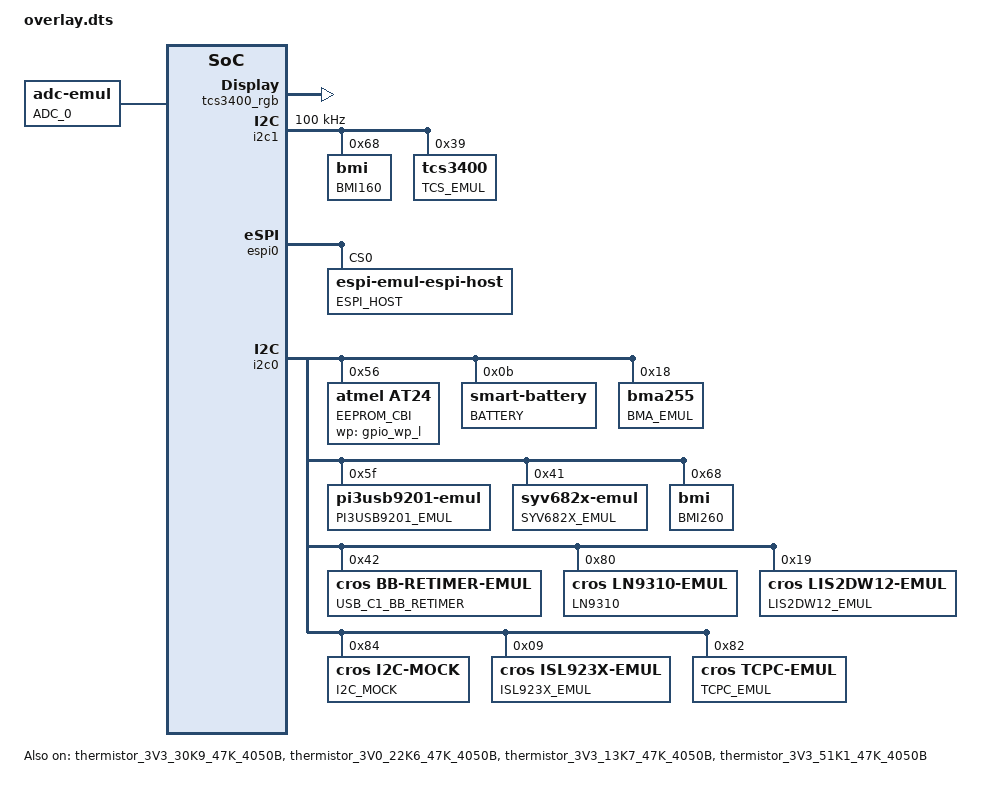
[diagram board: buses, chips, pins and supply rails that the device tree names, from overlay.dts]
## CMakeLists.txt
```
# Copyright 2021 The ChromiumOS Authors
# Use of this source code is governed by a BSD-style license that can be
# found in the LICENSE file.

cmake_minimum_required(VERSION 3.13.1)
find_package(Zephyr REQUIRED HINTS "${ZEPHYR_BASE}")
project(drivers)

add_subdirectory(common)
add_subdirectory(${PLATFORM_EC}/zephyr/test/test_utils test_utils)

get_target_property(TEST_SOURCES app SOURCES)

# Add linked suites here
add_subdirectory_ifdef(CONFIG_LINK_TEST_SUITE_DEFAULT default)
add_subdirectory_ifdef(CONFIG_LINK_TEST_SUITE_DEFAULT_CONSOLE_CMDS default/src/console_cmd)
add_subdirectory_ifdef(CONFIG_LINK_TEST_SUITE_ACPI_STRINGS_FIFO acpi_strings_fifo)
add_subdirectory_ifdef(CONFIG_LINK_TEST_SUITE_AMD_FP6_USB_MUX amd_fp6_usb_mux)
add_subdirectory_ifdef(CONFIG_LINK_TEST_SUITE_ANX7447 anx7447)
add_subdirectory_ifdef(CONFIG_LINK_TEST_SUITE_AP_MUX_CONTROL ap_mux_control)
add_subdirectory_ifdef(CONFIG_LINK_TEST_SUITE_AP_POWER_EVENTS ap_power_events)
add_subdirectory_ifdef(CONFIG_LINK_TEST_SUITE_BMI3XX bmi3xx)
add_subdirectory_ifdef(CONFIG_LINK_TEST_SUITE_BATTERY_CONFIG battery_config)
add_subdirectory_ifdef(CONFIG_LINK_TEST_SUITE_CBI_FLASH cbi_flash)
add_subdirectory_ifdef(CONFIG_LINK_TEST_SUITE_CBI_FLASH_FROM_EEPROM cbi_flash)
add_subdirectory_ifdef(CONFIG_LINK_TEST_SUITE_CEC_COMMON cec_common)
add_subdirectory_ifdef(CONFIG_LINK_TEST_SUITE_CEC_BITBANG cec_bitbang)
add_subdirectory_ifdef(CONFIG_LINK_TEST_SUITE_CEC_IT83XX cec_it83xx)
add_subdirectory_ifdef(CONFIG_LINK_TEST_SUITE_CONSOLE_CMD_CRASH console_cmd_crash)
add_subdirectory_ifdef(CONFIG_LINK_TEST_SUITE_CONSOLE_CMD_MFALLOW console_cmd_mfallow)
add_subdirectory_ifdef(CONFIG_LINK_TEST_SUITE_CONSOLE_BUFFER console_buffer)
add_subdirectory_ifdef(CONFIG_LINK_TEST_SUITE_COMMON_CBI common_cbi)
add_subdirectory_ifdef(CONFIG_LINK_TEST_SUITE_COMMON_CBI_GPIO common_cbi_gpio)
add_subdirectory_ifdef(CONFIG_LINK_TEST_SUITE_COMMON_CHARGER common_charger)
add_subdirectory_ifdef(CONFIG_LINK_TEST_SUITE_CHARGE_MANAGER charge_manager)
add_subdirectory_ifdef(CONFIG_LINK_TEST_SUITE_CHARGESPLASH chargesplash)
add_subdirectory_ifdef(CONFIG_LINK_TEST_SUITE_CROS_FLASH cros_flash)
add_subdirectory_ifdef(CONFIG_LINK_TEST_SUITE_FAN fan)
add_subdirectory_ifdef(CONFIG_LINK_TEST_SUITE_FLASH flash)
add_subdirectory_ifdef(CONFIG_LINK_TEST_SUITE_FPC1025 fpc1025)
add_subdirectory_ifdef(CONFIG_LINK_TEST_SUITE_ICM42607 icm42607)
add_subdirectory_ifdef(CONFIG_LINK_TEST_SUITE_ISL923X isl923x)
add_subdirectory_ifdef(CONFIG_LINK_TEST_SUITE_ISL9241 isl9241)
add_subdirectory_ifdef(CONFIG_LINK_TEST_SUITE_I2C_CONTROLLER i2c_controller)
add_subdirectory_ifdef(CONFIG_LINK_TEST_SUITE_IT8XXX2_HW_SHA256 it8xxx2_hw_sha256)
add_subdirectory_ifdef(CONFIG_LINK_TEST_SUITE_KEYBOARD_8042 keyboard_8042)
add_subdirectory_ifdef(CONFIG_LINK_TEST_SUITE_KEYBOARD_SCAN keyboard_scan)
add_subdirectory_ifdef(CONFIG_LINK_TEST_SUITE_LED_DRIVER led_driver)
add_subdirectory_ifdef(CONFIG_LINK_TEST_SUITE_LED_DRIVER_ALIAS_LED led_driver)
add_subdirectory_ifdef(CONFIG_LINK_TEST_SUITE_LED_DRIVER_CUSTOM led_driver)
add_subdirectory_ifdef(CONFIG_LINK_TEST_SUITE_LED_DRIVER_SEQUENCE led_driver)
add_subdirectory_ifdef(CONFIG_LINK_TEST_SUITE_LED_DRIVER_MAX695X led_driver)
add_subdirectory_ifdef(CONFIG_LINK_TEST_SUITE_LIS2DH lis2dh)
add_subdirectory_ifdef(CONFIG_LINK_TEST_SUITE_LSM6DSM lsm6dsm)
add_subdirectory_ifdef(CONFIG_LINK_TEST_SUITE_MKBP mkbp)
add_subdirectory_ifdef(CONFIG_LINK_TEST_SUITE_NCT38XX nct38xx)
add_subdirectory_ifdef(CONFIG_LINK_TEST_SUITE_NX20P348X nx20p348x)
add_subdirectory_ifdef(CONFIG_LINK_TEST_SUITE_ONE_WIRE_UART one_wire_uart)
add_subdirectory_ifdef(CONFIG_LINK_TEST_SUITE_PANIC panic)
add_subdirectory_ifdef(CONFIG_LINK_TEST_SUITE_PANIC_LOG panic_log)
add_subdirectory_ifdef(CONFIG_LINK_TEST_SUITE_PANIC_OUTPUT panic_output)
add_subdirectory_ifdef(CONFIG_LINK_TEST_SUITE_PRESERVED_RING_BUF preserved_ring_buf)
add_subdirectory_ifdef(CONFIG_LINK_TEST_SUITE_PANIC_REASON panic_reason)
add_subdirectory_ifdef(CONFIG_LINK_TEST_SUITE_POWER_HOST_SLEEP power_host_sleep)
add_subdirectory_ifdef(CONFIG_LINK_TEST_SUITE_RT1718S rt1718s)
add_subdirectory_ifdef(CONFIG_LINK_TEST_SUITE_KTU1125 ktu1125)
add_subdirectory_ifdef(CONFIG_LINK_TEST_SUITE_RAA489000 raa489000)
add_subdirectory_ifdef(CONFIG_LINK_TEST_SUITE_RT1715 rt1715)
add_subdirectory_ifdef(CONFIG_LINK_TEST_SUITE_RT1739 rt1739)
add_subdirectory_ifdef(CONFIG_LINK_TEST_SUITE_RT9490 rt9490)
add_subdirectory_ifdef(CONFIG_LINK_TEST_SUITE_RANDOM random)
add_subdirectory_ifdef(CONFIG_LINK_TEST_SUITE_SHIM_ESPI shim_espi)
add_subdirectory_ifdef(CONFIG_LINK_TEST_SUITE_SHIM_GPIO_ID shim_gpio_id)
add_subdirectory_ifdef(CONFIG_LINK_TEST_SUITE_SHIM_PWM_HC shim_pwm_hc)
add_subdirectory_ifdef(CONFIG_LINK_TEST_SUITE_SHIM_RTC shim_rtc)
add_subdirectory_ifdef(CONFIG_LINK_TEST_SUITE_SMART_BATTERY smart_battery)
add_subdirectory_ifdef(CONFIG_LINK_TEST_SUITE_SMART_BATTERY_PRESENT smart_battery)
add_subdirectory_ifdef(CONFIG_LINK_TEST_SUITE_SMART_BATTERY_DEADBAND smart_battery)
add_subdirectory_ifdef(CONFIG_LINK_TEST_SUITE_TIMER timer)
add_subdirectory_ifdef(CONFIG_LINK_TEST_SUITE_UFSC_PDC ufsc_pdc)
add_subdirectory_ifdef(CONFIG_LINK_TEST_SUITE_UFSC_POLICIES ufsc_policies)
add_subdirectory_ifdef(CONFIG_LINK_TEST_SUITE_UPSTREAM_FUEL_GAUGE upstream_fuel_gauge)
add_subdirectory_ifdef(CONFIG_LINK_TEST_SUITE_USB_COMMON usb_common)
add_subdirectory_ifdef(CONFIG_LINK_TEST_SUITE_USB_MALFUNCTION_SINK usb_malfunction_sink)
add_subdirectory_ifdef(CONFIG_LINK_TEST_SUITE_USB_PD_DISCOVERY usb_pd_discovery)
add_subdirectory_ifdef(CONFIG_LINK_TEST_SUITE_USB_PD_DPS dps)
add_subdirectory_ifdef(CONFIG_LINK_TEST_SUITE_USB_PORT_POWER_DUMB usb_port_power_dumb)
add_subdirectory_ifdef(CONFIG_LINK_TEST_SUITE_USB_RETIMER_FW_UPDATE usb_retimer_fw_update)
add_subdirectory_ifdef(CONFIG_LINK_TEST_SUITE_USBC_ALT_MODE usbc_alt_mode)
add_subdirectory_ifdef(CONFIG_LINK_TEST_SUITE_USBC_CONSOLE_PD usbc_console_pd)
add_subdirectory_ifdef(CONFIG_LINK_TEST_SUITE_USBC_CTVPD usbc_ctvpd)
add_subdirectory_ifdef(CONFIG_LINK_TEST_SUITE_USBC_FRS usbc_frs)
add_subdirectory_ifdef(CONFIG_LINK_TEST_SUITE_USBC_SVDM_DFP_ONLY usbc_svdm_dfp_only)
add_subdirectory_ifdef(CONFIG_LINK_TEST_SUITE_USBC_POWER_CONTRACT usbc_power_contract)
add_subdirectory_ifdef(CONFIG_LINK_TEST_SUITE_USBC_DP_MODE usbc_dp_mode)
add_subdirectory_ifdef(CONFIG_LINK_TEST_SUITE_USBC_TBT_MODE usbc_tbt_mode)
add_subdirectory_ifdef(CONFIG_LINK_TEST_SUITE_USBC_RETIMER usbc_retimer)
add_subdirectory_ifdef(CONFIG_LINK_TEST_SUITE_USBC_USB4_MODE usbc_usb4_mode)
add_subdirectory_ifdef(CONFIG_LINK_TEST_SUITE_USBC_VCONN_SWAP usbc_vconn_swap)
add_subdirectory_ifdef(CONFIG_LINK_TEST_SUITE_USBC_OCP usbc_ocp)
add_subdirectory_ifdef(CONFIG_LINK_TEST_SUITE_USBC_PPC usbc_ppc)
add_subdirectory_ifdef(CONFIG_LINK_TEST_SUITE_USBC_TCPC usbc_tcpc)
add_subdirectory_ifdef(CONFIG_LINK_TEST_SUITE_USBC_SM usbc_sm)
add_subdirectory_ifdef(CONFIG_LINK_TEST_SUITE_USBC_FAKE_PDOS usbc_fake_pdos)
add_subdirectory_ifdef(CONFIG_LINK_TEST_SUITE_HOST_COMMANDS host_cmd)
add_subdirectory_ifdef(CONFIG_LINK_TEST_SUITE_HOST_COMMAND_READ_MEMMAP host_cmd_read_memmap)
add_subdirectory_ifdef(CONFIG_LINK_TEST_SUITE_SYSTEM system)
add_subdirectory_ifdef(CONFIG_LINK_TEST_SUITE_LOCATE_CHIP_ALTS locate_chip)
add_subdirectory_ifdef(CONFIG_LINK_TEST_SUITE_BUTTON button)
add_subdirectory_ifdef(CONFIG_LINK_TEST_SUITE_CONSOLE console)
add_subdirectory_ifdef(CONFIG_LINK_TEST_SUITE_HOST_CMD_THREAD host_command_thread)
add_subdirectory_ifdef(CONFIG_LINK_TEST_SUITE_BC12_UPSTREAM bc12_upstream)
add_subdirectory_ifdef(CONFIG_LINK_TEST_SUITE_PI3USB9201 bc12_pi3usb9201)
add_subdirectory_ifdef(CONFIG_LINK_TEST_SUITE_MEMMAP memmap)
add_subdirectory_ifdef(CONFIG_LINK_TEST_SUITE_LED_COMMON led_common)
add_subdirectory_ifdef(CONFIG_LINK_TEST_SUITE_PS8743 ps8743)
add_subdirectory_ifdef(CONFIG_LINK_TEST_SUITE_PS8XXX ps8xxx)
add_subdirectory_ifdef(CONFIG_LINK_TEST_SUITE_GPIO_INIT gpio_init)
add_subdirectory_ifdef(CONFIG_LINK_TEST_SUITE_GPIO_UNHOOK gpio_unhook)
add_subdirectory_ifdef(CONFIG_LINK_TEST_SUITE_ANX7452 anx7452)
add_subdirectory_ifdef(CONFIG_LINK_TEST_SUITE_KB8010 kb8010)
add_subdirectory_ifdef(CONFIG_LINK_TEST_SUITE_SM5803 sm5803)
add_subdirectory_ifdef(CONFIG_LINK_TEST_SUITE_BODY_DETECTION body_detection)
add_subdirectory_ifdef(CONFIG_LINK_TEST_SUITE_MOTION_SENSE_BUS_AP_OFF motion_sense_bus_ap_off)
add_subdirectory_ifdef(CONFIG_LINK_TEST_SUITE_WATCHDOG watchdog)
add_subdirectory_ifdef(CONFIG_LINK_TEST_SUITE_WATCHDOG_HELPER watchdog_helper)
add_subdirectory_ifdef(CONFIG_LINK_TEST_SUITE_LED_PWM_FADE led_pwm_fade)
add_subdirectory_ifdef(CONFIG_LINK_TEST_SUITE_TABLETMODE_INTERRUPT tabletmode_interrupt)
add_subdirectory_ifdef(CONFIG_LINK_TEST_SUITE_WRITE_PROTECTION_EXTERNAL write_protection_external)
add_subdirectory_ifdef(CONFIG_LINK_TEST_SUITE_IT8XXX2 it8xxx2)
add_subdirectory_ifdef(CONFIG_LINK_TEST_SUITE_RT3645 rt3645)

get_target_property(TEST_SOURCES_NEW app SOURCES)

# Check to make sure at least one suite was added
list(REMOVE_ITEM TEST_SOURCES_NEW ${TEST_SOURCES})
if(NOT TEST_SOURCES_NEW)
  message(FATAL_ERROR "Invalid configuration, must add test sources")
endif()

set_compiler_property(APPEND PROPERTY coverage -O0)
```

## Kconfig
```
# Copyright 2022 The ChromiumOS Authors
# Use of this source code is governed by a BSD-style license that can be
# found in the LICENSE file.

config TEST_PROVIDE_PM_HOOKS
	bool "Provide PM hooks for test purposes"
	default y
	select HAS_PM

config BUG_249829957
	bool "Tracking b/249829957"

config LINK_TEST_SUITE_DEFAULT
	bool "Link and test the default test suite"

config LINK_TEST_SUITE_DEFAULT_CONSOLE_CMDS
	bool "Link and test the default console commands test suite"

config LINK_TEST_SUITE_CONSOLE_BUFFER
	bool "Link and test the console buffer test suite"

config LINK_TEST_SUITE_CONSOLE_CMD_CRASH
	bool "Link and test the console command crash test suite"

config LINK_TEST_SUITE_CONSOLE_CMD_MFALLOW
	bool "Link and test the console command mfallow test suite"

config LINK_TEST_SUITE_ACPI_STRINGS_FIFO
	bool "Link and test the ACPI strings FIFO tests"

config LINK_TEST_SUITE_AMD_FP6_USB_MUX
	bool "Link and test the AMD FP6 USB mux tests"

config LINK_TEST_SUITE_ANX7447
	bool "Link and test the anx7447 tests"

config LINK_TEST_SUITE_AP_MUX_CONTROL
	bool "Link and test the ap_mux_control tests"

config LINK_TEST_SUITE_AP_POWER_EVENTS
	bool "Link and test the ap_power_events driver tests"
	help
	  Verifies the AP power events driver which controls GPIOs
	  based on AP power state transitions.

config LINK_TEST_SUITE_BMI3XX
	bool "Link and test the bmi3xx tests"
	help
	  Include the BMI3XX driver test suite in the
	  binary.

config LINK_TEST_SUITE_BATTERY_CONFIG
	bool "Link and run battery_config CBI tests"
	help
	  Include tests for battery info in CBI.

config LINK_TEST_SUITE_BUTTON
	bool "Link tests for common/button.c"

config LINK_TEST_SUITE_CBI_FLASH
	bool "Link and execute the zephyr/shim/src/cbi/cbi_flash.c tests"
	help
	  Include the CBI Flash storage driver test suite
	  in the binary.

config LINK_TEST_SUITE_CBI_FLASH_FROM_EEPROM
	bool "Link and run CBI EEPROM to flash region tests"
	help
	  Include tests for migrating CBI EEPROM data to the flash based
	  CBI region.

config LINK_TEST_SUITE_CEC_COMMON
	bool "Link and run the common/cec.c tests"

config LINK_TEST_SUITE_CEC_BITBANG
	bool "Link and run tests for driver/cec/bitbang"

config LINK_TEST_SUITE_CEC_IT83XX
	bool "Link and run tests for driver/cec/it83xx"

config LINK_TEST_SUITE_CHARGE_MANAGER
	bool "Link and test the charge manager tests"

config LINK_TEST_SUITE_CHARGESPLASH
	bool "Link and test the chargesplash tests"

config LINK_TEST_SUITE_COMMON_CBI
	bool "Link and execute the common/cbi.c tests"

config LINK_TEST_SUITE_COMMON_CBI_GPIO
	bool "Link and execute the common/cbi_gpio.c tests"

config LINK_TEST_SUITE_COMMON_CHARGER
	bool "Link and execute the common/charger.c tests"

config LINK_TEST_SUITE_FAN
	bool "Link and test the fan tests"

config LINK_TEST_SUITE_CROS_FLASH
	bool "Link and execute the cros-flash driver tests"
	help
	  Include the test suite exercising cros-flash driver in the binary.

config LINK_TEST_SUITE_FLASH
	bool "Link and execute the common/flash.c tests"
	help
	  Include the test suite exercising flash-related code in the binary.

config LINK_TEST_SUITE_GPIO_INIT
  	bool "Link and execute the GPIO init tests"

config LINK_TEST_SUITE_GPIO_UNHOOK
  	bool "Link and execute the unhooked gpio tests"

config LINK_TEST_SUITE_HOST_COMMANDS
	select PLATFORM_EC_CHARGE_STATE_DEBUG
	bool "Link and test the host command tests"

config LINK_TEST_SUITE_HOST_COMMAND_READ_MEMMAP
	bool "Link and test the host command read memmap tests"

config LINK_TEST_SUITE_ICM42607
	bool "Link and test the icm42607 tests"

config LINK_TEST_SUITE_ISL923X
	bool "Link and test the isl923x tests"

config LINK_TEST_SUITE_ISL9241
	bool "Link and test the isl9241 tests"

config LINK_TEST_SUITE_I2C_CONTROLLER
	bool "Link and test the i2c_controller tests"

config LINK_TEST_SUITE_IT8XXX2_HW_SHA256
	bool "Link and test the it8xxx2_hw_sha256 tests"
	help
	  Include the it8xxx2_hw_sha256 test suite
	  in the binary.

config LINK_TEST_SUITE_KEYBOARD_8042
	bool "Link and test the keyboard_8042 tests"

config LINK_TEST_SUITE_KEYBOARD_SCAN
	bool "Link and test the keyboard_scan tests"
	select PLATFORM_EC_MKBP_EVENT_WAKEUP_MASK
	select PLATFORM_EC_MKBP_HOST_EVENT_WAKEUP_MASK

config LINK_TEST_SUITE_LED_DRIVER
	bool "Link and test the led_driver tests"

config LINK_TEST_SUITE_LED_DRIVER_ALIAS_LED
	bool "Link and test the led_driver tests with alias LEDs defined"

config LINK_TEST_SUITE_LED_DRIVER_CUSTOM
	bool "Link and test the LED custom pattern logic"

config LINK_TEST_SUITE_LED_DRIVER_SEQUENCE
	bool "Link and test the LED pattern sequence logic"

config LINK_TEST_SUITE_LOCATE_CHIP_ALTS
	bool "Link tests for alternate operations of the locate chip host cmd"
	help
	  Compile a binary that allows the non herobrine paths of the locate
	  chip command to execute

config LINK_TEST_SUITE_LIS2DH
	bool "Link tests for lis2dh driver"

config LINK_TEST_SUITE_LSM6DSM
	bool "Link tests for lsm6dsm driver"

config LINK_TEST_SUITE_LSM6DSO
	bool "Link tests for lsm6dso driver"

config LINK_TEST_SUITE_LED_DRIVER_MAX695X
	bool "Link and test the MAX695x 7-segment display driver tests"
	help
	  Include the MAX695x driver test suite.
	  Tests the 7-segment LED display driver functionality including
	  initialization, display operations, and console commands.

config LINK_TEST_SUITE_MKBP
	bool "Link and test the mkbp tests"

config LINK_TEST_SUITE_NCT38XX
	bool "Link and test the nct38xx tests"

config LINK_TEST_SUITE_NX20P348X
	bool "Link and test the nx20p348x tests"
	select PLATFORM_EC_CONSOLE_CMD_PPC_DUMP
	select PLATFORM_EC_USB_PD_LOGGING

config LINK_TEST_SUITE_PANIC
	bool "Link and test the panic tests"

config LINK_TEST_SUITE_PANIC_OUTPUT
	bool "Link and test the panic_output tests"

config LINK_TEST_SUITE_PANIC_REASON
	bool "Link and test the panic_reason tests"

config LINK_TEST_SUITE_PANIC_LOG
	bool "Link and test the panic log tests"

config LINK_TEST_SUITE_PRESERVED_RING_BUF
	bool "Link and test the preserved ring buf tests"

config LINK_TEST_SUITE_POWER_HOST_SLEEP
	bool "Link and run the power/host_sleep.c specific tests"

config LINK_TEST_SUITE_PS8743
	bool "Link and test the ps8743 tests"
	help
	  Link tests PS8743 test suite for the MUX driver related function
	  tests.

config LINK_TEST_SUITE_PS8XXX
	bool "Link and test the ps8xxx tests"

config LINK_TEST_SUITE_RAA489000
	bool "Link and test the raa489000 tests"
	help
	  Link raa489000 test suite for the TCPM driver related function
	  tests.

config LINK_TEST_SUITE_RT1715
	bool "Link and test the rt17115 tests"
	help
	  Link rt1715 test suite for the TCPM driver related function
	  tests.

config LINK_TEST_SUITE_IT8XXX2
	bool "Link and test the it8xxx2 tests"
	help
	  Link it8xxx2 test suite for the TCPM driver related function
	  tests.


config LINK_TEST_SUITE_RT1718S
	bool "Link and test the rt1718s tests"
	help
	  Link tests rt1718s test suite for the TCPM driver related function
	  tests.

config LINK_TEST_SUITE_RT1739
	bool "Link and test the rt1739 tests"
	help
	  Link tests rt1739s test suite for the PPC driver related function
	  tests.

config LINK_TEST_SUITE_KTU1125
	bool "Link and test the ktu1125 tests"
	help
	  Link tests ktu1125 test suite for the PPC driver related function
	  tests.

config LINK_TEST_SUITE_RT9490
	bool "Link and test the rt9490 tests"

config LINK_TEST_SUITE_WATCHDOG
	bool "Link and test the watchdog tests"
	select PLATFORM_EC_CONSOLE_CMD_WATCHDOG_INFO
	select PLATFORM_EC_HOSTCMD_WATCHDOG_INFO

config LINK_TEST_SUITE_WATCHDOG_HELPER
	bool "Link and run watchdog helper tests"
	help
	  Include the test suite exercising the Watchdog Helper utility.

config LINK_TEST_SUITE_RANDOM
	bool "Link and run random (trng) tests"
	help
	  Include the test suite exercising RNG code in the binary.

config LINK_TEST_SUITE_SHIM_ESPI
	bool "Link and run the eSPI shim tests"

config LINK_TEST_SUITE_SHIM_GPIO_ID
	bool "Link and run the gpio tests"

config LINK_TEST_SUITE_SHIM_PWM_HC
	bool "Link and run the shim pwm_hc tests"

config LINK_TEST_SUITE_SHIM_RTC
	bool "Link and run the shim rtc tests"

config LINK_TEST_SUITE_SYSTEM
	bool "Link tests for common system code"

config LINK_TEST_SUITE_TIMER
	bool "Link and test the timer tests"

config LINK_TEST_SUITE_UFSC_PDC
	bool "Link and test the UFSC PDC selector"
	help
	  Include the test suite exercising the UFSC PDC selector logic.

config LINK_TEST_SUITE_UFSC_POLICIES
	bool "Link and test the UFSC policies"
	help
	  Include the test suite exercising the UFSC policies.

config LINK_TEST_SUITE_UPSTREAM_FUEL_GAUGE
	bool "Link and test usage of upstream fuel-gauge API"

config LINK_TEST_SUITE_USB_COMMON
	bool "Link and test USB common code tests"

config LINK_TEST_SUITE_USB_PD_DISCOVERY
	bool "Link and test USB PD discovery tests"

config LINK_TEST_SUITE_USB_MALFUNCTION_SINK
	bool "Link and test the usb_malfunction_sink tests"

config LINK_TEST_SUITE_USB_PD_DPS
	bool "Link and test the dps tests"

config LINK_TEST_SUITE_USB_PORT_POWER_DUMB
	bool "Link and test the usb_port_power_dumb tests"

config LINK_TEST_SUITE_USB_RETIMER_FW_UPDATE
	bool "Link and test the usb_retimer_fw_update tests"

config LINK_TEST_SUITE_USBC_ALT_MODE
	bool "Link and test the usbc_alt_mode tests"

config LINK_TEST_SUITE_USBC_CONSOLE_PD
	bool"Link and test the usbc_console_pd tests"

config LINK_TEST_SUITE_USBC_CTVPD
	bool "Link tests for charge-through VCONN-powered device support"
	select EMUL_TCPCI_PARTNER_VPD
	select LOG

config LINK_TEST_SUITE_USBC_FRS
	bool "Link tests for fast role swap support"
	select LOG
	select PLATFORM_EC_USB_PD_FRS

config LINK_TEST_SUITE_USBC_POWER_CONTRACT
	bool "Link tests for USBC Power Contract"
	select LOG

config LINK_TEST_SUITE_USBC_OCP
	bool "Link tests for common USBC OCP code"

config LINK_TEST_SUITE_USBC_PPC
	bool "Link tests for common USBC PPC code"

config LINK_TEST_SUITE_USBC_TCPC
	bool "Link tests for common USBC TCPC code"
	help
	  Include the USBC TCPC test suite in the
	  binary.

config LINK_TEST_SUITE_USBC_SM
	bool "Link tests for common USBC state machine code"
	help
	  Include the USBC SM test suite in the
	  binary.

config LINK_TEST_SUITE_USBC_SVDM_DFP_ONLY
	bool "Link and test the usbc_svdm_dfp_only tests"

config LINK_TEST_SUITE_USBC_RETIMER
	bool "Link the USBC retimer tests"

config LINK_TEST_SUITE_USBC_RETIMER_ANX7483
	bool "Link and test the ANX7484 tests"
	select LINK_TEST_SUITE_USBC_RETIMER
	select PLATFORM_EC_USBC_RETIMER_ANX7483
	help
	  Include the ANX7483 test suite in the binary.

config LINK_TEST_SUITE_USBC_RETIMER_PS8811
	bool "Link and test the PS8811 tests"
	select LINK_TEST_SUITE_USBC_RETIMER
	select PLATFORM_EC_USBC_RETIMER_PS8811
	help
	  Include the PS8811 test suite in the binary.

config LINK_TEST_SUITE_USBC_DP_MODE
	bool "Link and test the usbc_dp_tests"
	help
	  Include the DP 2.1 test suite in the binary, testing the 2.1 SVDM version.

config LINK_TEST_SUITE_USBC_DP_MODE_20
	bool "Link and test the usbc_dp_tests_20"
	help
	  Include the DP 2.1 test suite in the binary, testing the 2.0 SVDM version.

config LINK_TEST_SUITE_USBC_TBT_MODE
	bool "Link and test the usbc_tbt_mode tests"

config LINK_TEST_SUITE_USBC_USB4_MODE
	bool "Link and test the usbc_usb4_mode tests"
	help
	  Include the usbc_usb4 test suite in the binary.

config LINK_TEST_SUITE_USBC_VCONN_SWAP
	bool "Link and test the usbc_vconn_swap tests"
	help
	  Include the test suite exercising VCONN Swap behaviors in the binary.

config LINK_TEST_SUITE_USBC_FAKE_PDOS
	bool "Link and test the usbc_fake_pdos tests"
	help
	  Include the test suite exercising non-standard PDO behaviors in the
	  binary.

config LINK_TEST_SUITE_CONSOLE
	bool "Link and test the console tests"
	select UART_INTERRUPT_DRIVEN

config LINK_TEST_SUITE_HOST_CMD_THREAD
	bool "Link and test the host command thread override tests"

config LINK_TEST_SUITE_BC12_UPSTREAM
	bool "Link and test the BC1.2 upsstream tests"
	help
	  This test suite validates integration of the EC application with
	  the upstream Zephyr BC1.2 driver API.

config LINK_TEST_SUITE_PI3USB9201
	bool "Link and test the pi3usb9201 tests"

config LINK_TEST_SUITE_MEMMAP
	bool "Link and test memory mapped tests for common/flash.c"
	select PLATFORM_EC_MAPPED_STORAGE

config LINK_TEST_SUITE_LED_COMMON
	bool "Link and test the led_common.c file"
	depends on !PLATFORM_EC_LED_DT
	select PLATFORM_EC_LED_COMMON

config LINK_TEST_SUITE_ANX7452
	bool "Link and test the anx7452 tests"
	help
	  Include the test suite of ANX7452 retimer in the binary. The tests
	  use I2C emulation.

config LINK_TEST_SUITE_KB8010
	bool "Link and test the kb8010 tests"
	help
	  Link tests kb8010 test suite for the retimer driver related
	  function tests.

config LINK_TEST_SUITE_SM5803
	bool "Link and test the SM5803 charger tests"

config LINK_TEST_SUITE_BODY_DETECTION
	bool "Link and test the body detection tests"
	help
	  Include the test suite exercising body detection behaviors in the binary.

config LINK_TEST_SUITE_LED_PWM_FADE
	bool "Link and test the led_pwm_fade.c tests"

config LINK_TEST_SUITE_ONE_WIRE_UART
	bool "Link and test the one wire uart driver tests"

config LINK_TEST_SUITE_SMART_BATTERY
	bool "Link and test the smart battery driver tests"

config LINK_TEST_SUITE_SMART_BATTERY_PRESENT
	bool "Link and test the smart battery present driver tests"

config LINK_TEST_SUITE_SMART_BATTERY_DEADBAND
	bool "Link and test the smart battery deadband driver tests"

config LINK_TEST_SUITE_TABLETMODE_INTERRUPT
	bool "Link and test the tabletmode interrupt driver tests"
	help
	  Verifies a singleton driver which handles an external interrupt
	  signaling to the EC when to switch in or out of tablet mode.

config LINK_TEST_SUITE_WRITE_PROTECTION_EXTERNAL
	bool "Link and test the write protection tests"
	help
	  Verifies functionality of external write protection

config LINK_TEST_SUITE_RT3645
	bool "Link and test rt3645 tests"
	help
	  Verifies functionality of rt3645 IMVP driver

source "Kconfig.zephyr"
```

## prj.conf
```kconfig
# Copyright 2021 The ChromiumOS Authors
# Use of this source code is governed by a BSD-style license that can be
# found in the LICENSE file.

# Enabling this config will show all I2C traffic, do not commit with this line
# uncommented, it is here to make it easy to find/enable.
# CONFIG_I2C_LOG_LEVEL_DBG=y

CONFIG_ZTEST=y
CONFIG_ZTEST_ASSERT_VERBOSE=1
CONFIG_ZTEST_MOCKING=y
CONFIG_ZTEST_PARAMETER_COUNT=24
CONFIG_TEST=y
CONFIG_PLATFORM_EC_DEBUG_ASSERT=y
# Do not set CONFIG_ASSERT_TEST=y here, it will mask assert failures.
# Instead set CONFIG_ASSERT_TEST=y only on specific tests that require it.
CONFIG_ASSERT_TEST=n
CONFIG_SHELL_VT100_COMMANDS=n

# Print logs from Zephyr LOG_MODULE to stdout
CONFIG_UART_NATIVE_PTY_0_ON_STDINOUT=y

CONFIG_PLATFORM_EC_AP_HANG_DETECT=y

# Simulate 10 ticks per ms
CONFIG_SYS_CLOCK_TICKS_PER_SEC=10000
CONFIG_TASKS_SET_TEST_RUNNER_TID_RULE=y

# Enable exception stack traces for better errors
CONFIG_EXCEPTION_STACK_TRACE=y

# Enable debugging features
CONFIG_DEBUG=y
CONFIG_X86_DEBUG_INFO=y
CONFIG_DEBUG_OPTIMIZATIONS=y
CONFIG_PLATFORM_EC_CONSOLE_DEBUG=n
CONFIG_SHELL_BACKEND_DUMMY=y
CONFIG_SHELL_BACKEND_SERIAL=n
# Shell dummy backend buffer needs to be big enough to capture reasonably
# large output messages. Note: a buffer larger than 2047 may cause result
# in messages being dropped due to Z_LOG_MSG_MAX_PACKAGE limit.
CONFIG_SHELL_BACKEND_DUMMY_BUF_SIZE=2000
CONFIG_SHELL_HELP=y
# We aren't using the serial console, but there is still a lot of code that
# assumes that a serial port exists.
CONFIG_SERIAL=y
CONFIG_RING_BUFFER=y
CONFIG_PLATFORM_EC_I2C_DEBUG_PASSTHRU=y

# Logging is configured to send output to the shell, disable
# the UART backed to prevent duplicate messages in the output.
CONFIG_LOG_BACKEND_UART=n

CONFIG_PLATFORM_EC=y
CONFIG_CROS_EC=y
CONFIG_SHIMMED_TASKS=y
CONFIG_EMUL=y
CONFIG_GPIO=y
CONFIG_PLATFORM_EC_GPIO_INIT_PRIORITY=49
CONFIG_EEPROM=y
CONFIG_EEPROM_SIMULATOR=n
CONFIG_EEPROM_AT2X_EMUL=y
CONFIG_EMUL_TCPCI_PARTNER_DRP=y
CONFIG_EMUL_TCPCI_PARTNER_FAULTY_EXT=y
CONFIG_PLATFORM_EC_CHARGE_MANAGER=y
CONFIG_PLATFORM_EC_CHARGE_RAMP_SW=y
CONFIG_PLATFORM_EC_CHARGESPLASH=y

CONFIG_PLATFORM_EC_POWERSEQ=y
CONFIG_PLATFORM_EC_CMD_PWR_AVG=y

CONFIG_PLATFORM_EC_EXTPOWER_GPIO=y

CONFIG_PLATFORM_EC_USB_PID=0x5000
CONFIG_PLATFORM_EC_USBC=y
CONFIG_PLATFORM_EC_USB_CHARGER=y
CONFIG_PLATFORM_EC_USB_POWER_DELIVERY=y
CONFIG_PLATFORM_EC_USB_PD_5V_EN_CUSTOM=y
CONFIG_PLATFORM_EC_CHARGER_DISCHARGE_ON_AC=y
CONFIG_PLATFORM_EC_CHARGER_DISCHARGE_ON_AC_CHARGER=y
<<<<<<< PATCH SET (744bca2e0323062202b4f00c09bb1573e3df7eeb charge_control: Support persisting charge limit to BBRAM)
CONFIG_PLATFORM_EC_CHARGE_CONTROL_PERSIST_TO_BBRAM=y
CONFIG_PLATFORM_EC_CHARGE_STATE_DEBUG=y
||||||| BASE      (61760131fbf53ec740a9e456fdf7a2f1b4fe04cf zephyr: system: Add BBRAM support for charge control persist)
CONFIG_PLATFORM_EC_CHARGE_STATE_DEBUG=y
=======
>>>>>>> BASE      (048bed6a24fd4275df284514a3b550a120449414 zephyr: system: Add BBRAM support for charge control persist)
CONFIG_PLATFORM_EC_I2C_VIRTUAL_BATTERY=y
CONFIG_PLATFORM_EC_CHARGER_SENSE_RESISTOR=10
CONFIG_PLATFORM_EC_CHARGER_SENSE_RESISTOR_AC=10
CONFIG_PLATFORM_EC_CHARGER_ISL9238=y
CONFIG_PLATFORM_EC_CHIP_INIT_ROM_REGION=y
CONFIG_PLATFORM_EC_USB_PD_VBUS_MEASURE_CHARGER=y
CONFIG_PLATFORM_EC_USB_PD_FRS=y
CONFIG_PLATFORM_EC_USB_PD_FRS_PPC=y
CONFIG_PLATFORM_EC_USB_PD_REV30=y
CONFIG_PLATFORM_EC_BATTERY_FUEL_GAUGE=y
CONFIG_PLATFORM_EC_HOSTCMD=y
CONFIG_PLATFORM_EC_USB_PD_TCPM_TUSB422=y
CONFIG_PLATFORM_EC_USB_MUX_RUNTIME_CONFIG=y
CONFIG_PLATFORM_EC_TEMP_SENSOR_POWER=y
CONFIG_PLATFORM_EC_SWITCH=y
CONFIG_PLATFORM_EC_SWITCHCAP_LN9310=y
CONFIG_PLATFORM_EC_ACCEL_BMA255=y
CONFIG_PLATFORM_EC_ACCELGYRO_BMI160=y
CONFIG_PLATFORM_EC_ACCELGYRO_BMI260=y
CONFIG_PLATFORM_EC_ACCELGYRO_BMI_COMM_I2C=y
CONFIG_PLATFORM_EC_ACCEL_FIFO=y
CONFIG_PLATFORM_EC_SENSOR_TIGHT_TIMESTAMPS=y
CONFIG_PLATFORM_EC_USB_PD_DISCHARGE=n
CONFIG_PLATFORM_EC_USB_PD_TCPM_MUX=y
CONFIG_PLATFORM_EC_USB_PD_TCPM_PS8805=y
CONFIG_PLATFORM_EC_USB_PD_TCPM_PS8805_FORCE_DID=y
CONFIG_PLATFORM_EC_USB_PD_TCPM_PS8815=y
CONFIG_PLATFORM_EC_USB_PD_TCPM_PS8815_FORCE_DID=y
CONFIG_PLATFORM_EC_USB_PD_TCPM_PS8745=y
CONFIG_PLATFORM_EC_USB_PD_TCPM_PS8745_FORCE_ID=y
CONFIG_PLATFORM_EC_USB_PD_TCPM_MULTI_PS8XXX=y
CONFIG_PLATFORM_EC_USB_PD_VBUS_DETECT_TCPC=y
CONFIG_PLATFORM_EC_USB_PD_REQUIRE_AP_MODE_ENTRY=y
CONFIG_PLATFORM_EC_USB_PD_CLEAR_HARD_RESET_STATUS=y
CONFIG_PLATFORM_EC_CONSOLE_CMD_WAITMS=y
CONFIG_PLATFORM_EC_POWER_SLEEP_FAILURE_DETECTION=y
CONFIG_PLATFORM_EC_CHIPSET_RESUME_INIT_HOOK=y
CONFIG_PLATFORM_EC_BATTERY_CUTOFF_TIMEOUT_MSEC=500

CONFIG_ESPI=y
CONFIG_EMUL_ESPI_HOST=y
CONFIG_ESPI_PERIPHERAL_ACPI_SHM_REGION=y
CONFIG_ESPI_PERIPHERAL_CUSTOM_OPCODE=y
CONFIG_ESPI_PERIPHERAL_EC_HOST_CMD=y

# Things that default to on, but aren't working yet
CONFIG_PLATFORM_EC_BACKLIGHT_LID=n
CONFIG_PLATFORM_EC_VBOOT_HASH=n
CONFIG_PLATFORM_EC_POWERSEQ_INTEL=n
CONFIG_PLATFORM_EC_POWERSEQ_PP5000_CONTROL=n

# USB-C
CONFIG_PLATFORM_EC_USBC_PPC_SYV682C=y
CONFIG_PLATFORM_EC_USBC_PPC_SYV682X=y

# Chipset for Herobrine
CONFIG_AP_ARM_QUALCOMM_SC7280=y
CONFIG_PLATFORM_EC_POWERSEQ_HOST_SLEEP=y

CONFIG_PLATFORM_EC_LID_SWITCH=y
CONFIG_PLATFORM_EC_POWER_BUTTON=y
CONFIG_PLATFORM_EC_HOST_INTERFACE_ESPI=y
CONFIG_PLATFORM_EC_PORT80=y
CONFIG_PLATFORM_EC_VSTORE_SLOT_COUNT=2
CONFIG_PLATFORM_EC_VOLUME_BUTTONS=y

CONFIG_WATCHDOG=y
CONFIG_WDT_DISABLE_AT_BOOT=y
CONFIG_PLATFORM_EC_USB_PD_HOST_CMD=y
CONFIG_PLATFORM_EC_KEYBOARD_PROTOCOL_MKBP=y
CONFIG_PLATFORM_EC_MKBP_EVENT=y
CONFIG_PLATFORM_EC_MKBP_USE_GPIO=y
CONFIG_PLATFORM_EC_MKBP_INPUT_DEVICES=y
CONFIG_FLASH=y
CONFIG_FLASH_PAGE_LAYOUT=y
CONFIG_PLATFORM_EC_VBOOT_HASH=y
CONFIG_PLATFORM_EC_CONSOLE_CMD_CHARGER_ADC_AMON_BMON=y
CONFIG_PLATFORM_EC_CHARGER_PSYS=y
CONFIG_PLATFORM_EC_CHARGER_PSYS_READ=y
CONFIG_PLATFORM_EC_CHARGE_RAMP_HW=y

CONFIG_PLATFORM_EC_CONSOLE_CMD_ACCELS=y
CONFIG_PLATFORM_EC_CONSOLE_CMD_ACCEL_INFO=y

CONFIG_PLATFORM_EC_ACCEL_SPOOF_MODE=y
CONFIG_PLATFORM_EC_CONSOLE_CMD_ACCEL_SPOOF=y

CONFIG_PLATFORM_EC_CONSOLE_CMD_MD=y

CONFIG_PLATFORM_EC_LID_ANGLE=y
CONFIG_PLATFORM_EC_TABLET_MODE=y

# Power Management (Herobrine arch enables this)
CONFIG_PM=y

CONFIG_INPUT=y

CONFIG_THREAD_MONITOR=y
CONFIG_PLATFORM_EC_HOSTCMD_THREAD_INFO=y
CONFIG_ARCH_STACKWALK=y
CONFIG_THREAD_STACK_INFO=y
CONFIG_SCHED_THREAD_USAGE=y
CONFIG_SCHED_THREAD_USAGE_ANALYSIS=y
CONFIG_THREAD_NAME=y
```

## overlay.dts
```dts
/* Copyright 2021 The Chromium OS Authors. All rights reserved.
 * Use of this source code is governed by a BSD-style license that can be
 * found in the LICENSE file.
 */

#include <dt-bindings/gpio_defines.h>
#include <cros/thermistor/thermistor.dtsi>

/ {
	aliases {
		bmi260-int = &ms_bmi260_accel;
		bmi160-int = &ms_bmi160_accel;
		lis2dw12-int = &ms_lis2dw12_accel;
		tcs3400-int = &tcs3400_clear;
	};
	named-gpios {
		compatible = "named-gpios";

		ec_batt_pres_odl {
			gpios = <&gpio0 1 GPIO_INPUT>;
			enum-name = "GPIO_BATT_PRES_ODL";
			label = "EC_BATT_PRES_ODL";
		};
		acok_od {
			gpios = <&gpio0 2 GPIO_INPUT>;
			enum-name = "GPIO_AC_PRESENT";
			label = "ACOK_OD";
		};
		/* In test WP is output because CBI use it, but it is also
		 * input, because test_all_tags set it to enable write
		 * protection.
		 */
		gpio_wp_l: wp_l {
			#gpio-cells = <0>;
			gpios = <&gpio0 3 (GPIO_INPUT | GPIO_OUTPUT)>;
			enum-name = "GPIO_WP_L";
			label = "WP_L";
		};
		pg_ec_dsw_pwrok {
			gpios = <&gpio0 4 GPIO_INPUT>;
			enum-name = "GPIO_PG_EC_DSW_PWROK";
			label = "PG_EC_DSW_PWROK";
		};
		ec_pch_wake_odl {
			gpios = <&gpio0 5 GPIO_OUT_HIGH>;
			enum-name = "GPIO_EC_PCH_WAKE_ODL";
			label = "EC_PCH_WAKE_ODL";
		};
		/* Setup USB C1 pin as output to check their state in test */
		usb_c1_ls_en {
			gpios = <&gpio0 6 (GPIO_INPUT | GPIO_PULL_UP |
					   GPIO_OUTPUT)>;
			enum-name = "GPIO_USB_C1_LS_EN";
			label = "USB_C1_LS_EN";
		};
		usb_c1_rt_rst_odl {
			gpios = <&gpio0 7 (GPIO_OUTPUT | GPIO_INPUT)>;
			enum-name = "GPIO_USB_C1_RT_RST_ODL";
			label = "USB_C1_RT_RST_ODL";
		};
	};
	named-i2c-ports {
		compatible = "named-i2c-ports";

		usb-c0 {
			i2c-port = <&i2c0>;
			enum-name = "I2C_PORT_USB_C0";
			label = "USB_C0";
		};
		usb-c1 {
			i2c-port = <&i2c0>;
			enum-name = "I2C_PORT_USB_C1";
			label = "USB_C1";
		};
		battery {
			i2c-port = <&i2c0>;
			enum-name = "I2C_PORT_BATTERY";
			label = "BATTERY";
		};
		power {
			i2c-port = <&i2c0>;
			enum-name = "I2C_PORT_POWER";
			label = "POWER";
		};
		charger {
			i2c-port = <&i2c0>;
			enum-name = "I2C_PORT_CHARGER";
			label = "CHARGER";
		};
		eeprom {
			i2c-port = <&i2c0>;
			enum-name = "I2C_PORT_EEPROM";
			label = "EEPROM";
		};
		i2c_accel: accel {
			i2c-port = <&i2c0>;
			enum-name = "I2C_PORT_ACCEL";
			label = "ACCEL";
		};
		i2c_sensor: sensor {
			i2c-port = <&i2c1>;
			enum-name = "I2C_PORT_SENSOR";
			label = "SENSOR";
		};
	};

	named-batteries {
		compatible = "named-batteries";

		lgc011 {
			enum-name = "lgc011";
		};
	};

	adc0: adc {
		compatible = "zephyr,adc-emul";
		nchannels = <4>;
		ref-internal-mv = <3300>;
		#io-channel-cells = <1>;
		label = "ADC_0";
		status = "okay";
	};

	named-adc-channels {
		compatible = "named-adc-channels";

		adc_charger: charger {
			label = "ADC_TEMP_SENSOR_CHARGER";
			enum-name = "ADC_TEMP_SENSOR_CHARGER";
			channel = <0>;
		};
		adc_pp3300_regulator: pp3300-regulator {
			label = "ADC_TEMP_SENSOR_PP3300_REGULATOR";
			enum-name = "ADC_TEMP_SENSOR_PP3300_REGULATOR";
			channel = <1>;
		};
		adc_ddr_soc: ddr-soc {
			label = "ADC_TEMP_SENSOR_DDR_SOC";
			enum-name = "ADC_TEMP_SENSOR_DDR_SOC";
			channel = <2>;
		};
		adc_fan: fan {
			label = "ADC_TEMP_SENSOR_FAN";
			enum-name = "ADC_TEMP_SENSOR_FAN";
			channel = <3>;
		};
	};

	named-temp-sensors {
		charger {
			thermistor = <&thermistor_3V3_13K7_47K_4050B>;
			status = "okay";
			compatible = "cros-ec,temp-sensor";
			label = "TEMP_SENSOR_CHARGER";
			enum-name = "TEMP_SENSOR_CHARGER";
			temp_fan_off = <40>;
			temp_fan_max = <55>;
			temp_host_high = <75>;
			temp_host_halt = <80>;
			temp_host_release_high = <65>;
			adc = <&adc_charger>;
		};
		pp3300-regulator {
			thermistor = <&thermistor_3V3_30K9_47K_4050B>;
			status = "okay";
			compatible = "cros-ec,temp-sensor";
			label = "TEMP_SENSOR_PP3300_REGULATOR";
			enum-name = "TEMP_SENSOR_PP3300_REGULATOR";
			temp_fan_off = <40>;
			temp_fan_max = <55>;
			temp_host_high = <75>;
			temp_host_halt = <80>;
			temp_host_release_high = <65>;
			adc = <&adc_pp3300_regulator>;
		};
		ddr-soc {
			thermistor = <&thermistor_3V3_51K1_47K_4050B>;
			status = "okay";
			compatible = "cros-ec,temp-sensor";
			label = "TEMP_SENSOR_DDR_SOC";
			enum-name = "TEMP_SENSOR_DDR_SOC";
			temp_fan_off = <35>;
			temp_fan_max = <50>;
			temp_host_high = <70>;
			temp_host_halt = <80>;
			temp_host_release_high = <65>;
			adc = <&adc_ddr_soc>;
		};
		fan {
			thermistor = <&thermistor_3V0_22K6_47K_4050B>;
			status = "okay";
			compatible = "cros-ec,temp-sensor";
			label = "TEMP_SENSOR_FAN";
			enum-name = "TEMP_SENSOR_FAN";
			temp_fan_off = <35>;
			temp_fan_max = <50>;
			temp_host_high = <70>;
			temp_host_halt = <80>;
			temp_host_release_high = <65>;
			adc = <&adc_fan>;
		};
	};

	/*
	 * Declare mutexes used by sensor drivers.
	 * A mutex node is used to create an instance of mutex_t.
	 * A mutex node is referenced by a sensor node if the
	 * corresponding sensor driver needs to use the
	 * instance of the mutex.
	 */
	motionsense-mutex {
		compatible = "cros-ec,motionsense-mutex";
		mutex_bmi260: bmi260-mutex {
			label = "BMI260_MUTEX";
		};

		mutex_bmi160: bmi160-mutex {
			label = "BMI160_MUTEX";
		};

		mutex_lis2dw12: lis2dw12-mutex {
			label = "LIS2DW12_MUTEX";
		};
	};

	/*
	 * Driver specific data. A driver-specific data can be shared with
	 * different motion sensors while they are using the same driver.
	 */
	motionsense-sensor-data {
		bmi260_data: bmi260-drv-data {
			compatible = "cros-ec,drvdata-bmi260";
			status = "okay";
		};

		bmi160_data: bmi160-drv-data {
			compatible = "cros-ec,drvdata-bmi160";
			status = "okay";
		};

		lis2dw12_data: lis2dw12-drv-data {
			compatible = "cros-ec,drvdata-lis2dw12";
			status = "okay";
		};

		tcs_clear_data: tcs3400-clear-drv-data {
			compatible = "cros-ec,drvdata-tcs3400-clear";
			status = "okay";

			als-drv-data {
				compatible = "cros-ec,accelgyro-als-drv-data";
				als-cal {
					scale = <1>;
					uscale = <0>;
					offset = <0>;
					als-channel-scale {
					compatible =
					"cros-ec,accelgyro-als-channel-scale";
						k-channel-scale = <1>;
						cover-scale = <1>;
					};
				};
			};
		};

		tcs_rgb_data: tcs3400-rgb-drv-data {
			compatible = "cros-ec,drvdata-tcs3400-rgb";
			status = "okay";

			/* node for rgb_calibration_t defined in accelgyro.h */
			rgb_calibration {
				compatible =
					"cros-ec,accelgyro-rgb-calibration";

				irt = <1>;

				rgb-cal-x {
					offset = <0>;
					coeff = <0 1 0 0>;
					als-channel-scale {
					compatible =
					"cros-ec,accelgyro-als-channel-scale";
						k-channel-scale = <1>;
						cover-scale = <1>;
					};
				};
				rgb-cal-y {
					offset = <0>;
					coeff = <0 0 1 0>;
					als-channel-scale {
					compatible =
					"cros-ec,accelgyro-als-channel-scale";
						k-channel-scale = <1>;
						cover-scale = <1>;
					};
				};
				rgb-cal-z {
					offset = <0>;
					coeff = <0 0 0 1>;
					als-channel-scale {
					compatible =
					"cros-ec,accelgyro-als-channel-scale";
						k-channel-scale = <1>;
						cover-scale = <1>;
					};
				};
			};
		};
	};

	/*
	 * List of motion sensors that creates motion_sensors array.
	 * The label "lid_accel" and "base_accel" are used to indicate
	 * motion sensor IDs for lid angle calculation.
	 */
	motionsense-sensor {
		ms_bmi260_accel: ms-bmi260-accel {
			compatible = "cros-ec,bmi260-accel";
			status = "okay";

			label = "BMI260 emul accel";
			location = "MOTIONSENSE_LOC_BASE";
			mutex = <&mutex_bmi260>;
			port = <&i2c_accel>;
			drv-data = <&bmi260_data>;
			default-range = <4>;
			i2c-spi-addr-flags = "BMI260_ADDR0_FLAGS";
		};

		ms_bmi260_gyro: ms-bmi260-gyro {
			compatible = "cros-ec,bmi260-gyro";
			status = "okay";

			label = "BMI260 emul gyro";
			location = "MOTIONSENSE_LOC_BASE";
			mutex = <&mutex_bmi260>;
			port = <&i2c_accel>;
			drv-data = <&bmi260_data>;
			default-range = <1000>; /* dps */
			i2c-spi-addr-flags = "BMI260_ADDR0_FLAGS";
		};

		ms_bmi160_accel: ms-bmi160-accel {
			compatible = "cros-ec,bmi160-accel";
			status = "okay";

			label = "BMI160 emul accel";
			location = "MOTIONSENSE_LOC_BASE";
			mutex = <&mutex_bmi160>;
			port = <&i2c_sensor>;
			drv-data = <&bmi160_data>;
			default-range = <4>;
			i2c-spi-addr-flags = "BMI160_ADDR0_FLAGS";
		};

		ms_bmi160_gyro: ms-bmi160-gyro {
			compatible = "cros-ec,bmi160-gyro";
			status = "okay";

			label = "BMI160 emul gyro";
			location = "MOTIONSENSE_LOC_BASE";
			mutex = <&mutex_bmi160>;
			port = <&i2c_sensor>;
			drv-data = <&bmi160_data>;
			default-range = <1000>; /* dps */
			i2c-spi-addr-flags = "BMI160_ADDR0_FLAGS";
		};

		ms_lis2dw12_accel: ms-lis2dw12-accel {
			compatible = "cros-ec,lis2dw12";
			status = "okay";

			label = "LIS2DW12";
			location = "MOTIONSENSE_LOC_BASE";
			mutex = <&mutex_lis2dw12>;
			port = <&i2c_accel>;
			drv-data = <&lis2dw12_data>;
			default-range = <2>;
			i2c-spi-addr-flags = "LIS2DWL_ADDR1_FLAGS";
		};

		tcs3400_clear: tcs3400-clear {
			compatible = "cros-ec,tcs3400-clear";
			status = "okay";

			label = "Clear Light";
			location = "MOTIONSENSE_LOC_BASE";
			port = <&i2c_sensor>;
			default-range = <0x10000>;
			drv-data = <&tcs_clear_data>;
			i2c-spi-addr-flags = "TCS3400_I2C_ADDR_FLAGS";
			configs {
				compatible =
					"cros-ec,motionsense-sensor-config";
				ec-s0 {
					/* Run ALS sensor in S0 */
					label = "SENSOR_CONFIG_EC_S0";
					odr = <1000>;
				};
			};
		};

		tcs3400_rgb: tcs3400-rgb {
			compatible = "cros-ec,tcs3400-rgb";
			status = "okay";

			label = "RGB Light";
			location = "MOTIONSENSE_LOC_BASE";
			default-range = <0x10000>; /* scale = 1x, uscale = 0 */
			drv-data = <&tcs_rgb_data>;
		};
	};

	/*
	 * Second i2c bus is required, because there is already device with
	 * address 0x68 on the first bus
	 */
	i2c1: i2c@400 {
		status = "okay";
		compatible = "zephyr,i2c-emul-controller";
		clock-frequency = <I2C_BITRATE_STANDARD>;
		#address-cells = <1>;
		#size-cells = <0>;
		reg = <0x400 4>;
		label = "I2C_1";

		accel_bmi160: bmi160@68 {
			compatible = "zephyr,bmi";
			reg = <0x68>;
			label = "BMI160";
			device-model = "BMI_EMUL_160";
			error-on-ro-write;
			error-on-wo-read;
			error-on-reserved-bit-write;
			simulate-command-exec-time;
		};

		tcs_emul: tcs@39 {
			compatible = "zephyr,tcs3400";
			reg = <0x39>;
			label = "TCS_EMUL";
			error-on-ro-write;
			error-on-reserved-bit-write;
			error-on-msb-first-access;
		};
	};
};

&espi0 {
	espi-host@0 {
		status = "okay";
		compatible = "zephyr,espi-emul-espi-host";
		reg = <0x0>;
		label = "ESPI_HOST";
	};
};

&gpio0 {
	ngpios = <8>;
};

&i2c0 {
	cbi_eeprom: eeprom@56 {
		compatible = "atmel,at24";
		reg = <0x56>;
		label = "EEPROM_CBI";
		size = <512>;
		pagesize = <8>;
		address-width = <8>;
		timeout = <5>;
		wp-gpios = <&gpio_wp_l>;
	};

	battery: sb@b {
		compatible = "zephyr,smart-battery";
		reg = <0xb>;
		label = "BATTERY";
		cycle-count = <99>;
		version = "BATTERY_SPEC_VER_1_1_WITH_PEC";
	};

	bma_emul: bma@18 {
		compatible = "zephyr,bma255";
		reg = <0x18>;
		label = "BMA_EMUL";
		error-on-compensation-not-ready;
		error-on-ro-write;
		error-on-reserved-bit-write;
		error-on-msb-first-access;
	};

	pi3usb9201_emul: pi3usb9201@5f {
		compatible = "zephyr,pi3usb9201-emul";
		reg = <0x5f>;
		label = "PI3USB9201_EMUL";
	};

	syv682x_emul: syv682x@41 {
		compatible = "zephyr,syv682x-emul";
		reg = <0x41>;
		label = "SYV682X_EMUL";
	};

	accel_bmi260: bmi260@68 {
		compatible = "zephyr,bmi";
		reg = <0x68>;
		label = "BMI260";
		device-model = "BMI_EMUL_260";
		error-on-ro-write;
		error-on-wo-read;
		error-on-reserved-bit-write;
		simulate-command-exec-time;
	};

	usb_c1_bb_retimer_emul: bbretimer@42 {
		compatible = "cros,bb-retimer-emul";
		reg = <0x42>;
		label = "USB_C1_BB_RETIMER";
		vendor = "BB_RETIMER_VENDOR_ID_1";
		error-on-ro-write;
		error-on-reserved-bit-write;
	};

	ln9310: ln9310@80 {
		compatible = "cros,ln9310-emul";
		status = "okay";
		reg = <0x80>;
		label = "LN9310";
	};

	lis2dw12_emul: lis2dw12@19 {
		compatible = "cros,lis2dw12-emul";
		status = "okay";
		reg = <0x19>;
		label = "LIS2DW12_EMUL";
	};

	i2c_mock: i2c_mock@84 {
		compatible = "cros,i2c-mock";
		status = "okay";
		reg = <0x84>;
		label = "I2C_MOCK";
	};

	isl923x_emul: isl923x@9 {
		compatible = "cros,isl923x-emul";
		status = "okay";
		reg = <0x9>;
		label = "ISL923X_EMUL";
	};

	tcpc_emul: tcpc_emul@82 {
		compatible = "cros,tcpc-emul";
		status = "okay";
		reg = <0x82>;
		label = "TCPC_EMUL";
		error-on-ro-write;
		error-on-reserved-bit-write;
		error-on-sequential-read;
		error-on-sequential-write;
	};
};

/* Enable all thermistors for testing */
&thermistor_3V3_30K9_47K_4050B  {
	status = "okay";
};

&thermistor_3V0_22K6_47K_4050B  {
	status = "okay";
};

&thermistor_3V3_13K7_47K_4050B  {
	status = "okay";
};

&thermistor_3V3_51K1_47K_4050B  {
	status = "okay";
};
```

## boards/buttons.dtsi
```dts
/* Copyright 2026 The ChromiumOS Authors
 * Use of this source code is governed by a BSD-style license that can be
 * found in the LICENSE file.
 */

#include <zephyr/dt-bindings/input/input-event-codes.h>

/ {
	cros_buttons: buttons {
		compatible = "gpio-keys";
		zephyr,suspend-action = "none";

		power_button: pwrbtn-ec-in-n {
			gpios = <&gpio0 25 GPIO_ACTIVE_LOW>;
			zephyr,code = <INPUT_KEY_POWER>;
		};

		vol_up: vol-up-ec {
			gpios = <&gpio1 4 GPIO_ACTIVE_LOW>;
			zephyr,code = <INPUT_KEY_VOLUMEUP>;
		};

		vol_down: vol-down-ec {
			gpios = <&gpio1 3 GPIO_ACTIVE_LOW>;
			zephyr,code = <INPUT_KEY_VOLUMEDOWN>;
		};
	};
};

/* Remove legacy GPIO definitions since they're now part of cros_buttons */
&gpio_ec_pwr_btn_odl {
	/delete-property/ enum-name;
};

&gpio_ec_volup_btn_odl {
	/delete-property/ enum-name;
};

&gpio_ec_voldn_btn_odl {
	/delete-property/ enum-name;
};
```

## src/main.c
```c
/* Copyright 2021 The Chromium OS Authors. All rights reserved.
 * Use of this source code is governed by a BSD-style license that can be
 * found in the LICENSE file.
 */

#include <zephyr.h>
#include <ztest.h>
#include "ec_app_main.h"

extern void test_suite_battery(void);
extern void test_suite_cbi(void);
extern void test_suite_smart_battery(void);
extern void test_suite_thermistor(void);
extern void test_suite_temp_sensor(void);
extern void test_suite_bma2x2(void);
extern void test_suite_bc12(void);
extern void test_suite_ppc(void);
extern void test_suite_bmi260(void);
extern void test_suite_bmi160(void);
extern void test_suite_tcs3400(void);
extern void test_suite_espi(void);
extern void test_suite_bb_retimer(void);
extern void test_suite_ln9310(void);
extern void test_suite_lis2dw12(void);
extern void test_suite_stm_mems_common(void);
extern void test_suite_isl923x(void);
extern void test_suite_tcpci(void);

void test_main(void)
{
	/* Test suites to run before ec_app_main.*/

	ec_app_main();

	/* Test suites to run after ec_app_main.*/
	test_suite_battery();
	test_suite_cbi();
	test_suite_smart_battery();
	test_suite_thermistor();
	test_suite_temp_sensor();
	test_suite_bma2x2();
	test_suite_bc12();
	test_suite_ppc();
	test_suite_bmi260();
	test_suite_bmi160();
	test_suite_tcs3400();
	test_suite_espi();
	test_suite_bb_retimer();
	test_suite_ln9310();
	test_suite_lis2dw12();
	test_suite_stm_mems_common();
	test_suite_isl923x();
	test_suite_tcpci();
}
```
